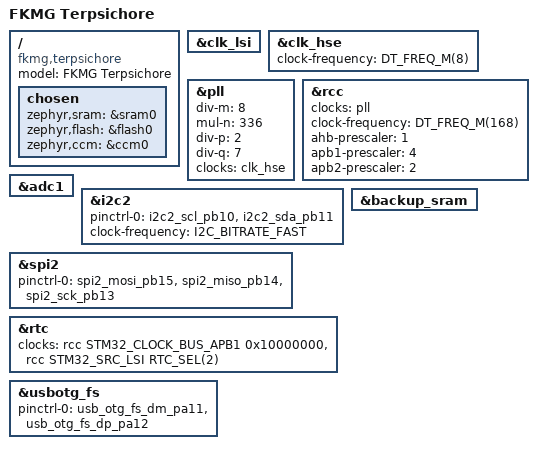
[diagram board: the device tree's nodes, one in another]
/*
 * Copyright (c) 2024 FKMG Circuits
 *
 * SPDX-License-Identifier: Apache-2.0
 */

 /dts-v1/;
 #include <st/f4/stm32f405Xg.dtsi>
 #include <st/f4/stm32f405rgtx-pinctrl.dtsi>
 #include <zephyr/dt-bindings/input/input-event-codes.h>
 
 / {
	 model = "FKMG Terpsichore";
	 compatible = "fkmg,terpsichore", "st,stm32f405";
 
	 chosen {
		//  zephyr,console = &usart1;
		//  zephyr,shell-uart = &usart1;
		 zephyr,sram = &sram0;
		 zephyr,flash = &flash0;
		 zephyr,ccm = &ccm0;
	 };
 
 };
 
 &clk_lsi {
	 status = "okay";
 };
 
 &clk_hse {
	 clock-frequency = <DT_FREQ_M(8)>;
	 status = "okay";
 };
 
 &pll {
	 div-m = <8>;
	 mul-n = <336>;
	 div-p = <2>;
	 div-q = <7>;
	 clocks = <&clk_hse>;
	 status = "okay";
 };
 
 &rcc {
	 clocks = <&pll>;
	 clock-frequency = <DT_FREQ_M(168)>;
	 ahb-prescaler = <1>;
	 apb1-prescaler = <4>;
	 apb2-prescaler = <2>;
 };
 
&adc1 {
	status = "okay";
};

 &i2c2 {
	 pinctrl-0 = <&i2c2_scl_pb10 &i2c2_sda_pb11>;
	 pinctrl-names = "default";
	 status = "okay";
	 clock-frequency = <I2C_BITRATE_FAST>;
 };
 
 &spi2 {
	pinctrl-0 = <&spi2_mosi_pb15 &spi2_miso_pb14 &spi2_sck_pb13>;
	pinctrl-names = "default";
	status = "okay";
 };
 
 &rtc {
	 clocks = <&rcc STM32_CLOCK_BUS_APB1 0x10000000>,
		  <&rcc STM32_SRC_LSI RTC_SEL(2)>;
	 status = "okay";
 };
 
 zephyr_udc0: &usbotg_fs {
	 pinctrl-0 = <&usb_otg_fs_dm_pa11 &usb_otg_fs_dp_pa12>;
	 pinctrl-names = "default";
	 status = "okay";
 };

 &backup_sram {
	 status = "okay";
 };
